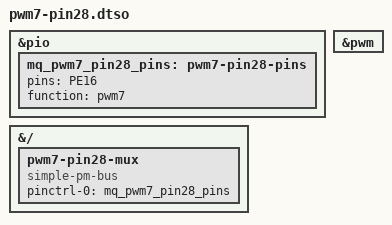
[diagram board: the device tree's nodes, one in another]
// SPDX-License-Identifier: (GPL-2.0+ OR MIT)
// Mangue OS header overlay pwm7-pin28 — GENERATED by tools/gen_overlays.py,
// edit overlays/header_table.py instead.
//
// pin port  role
//  28 PE16  pwm7
// device: /sys/class/pwm/pwmchip0 channel 7

/dts-v1/;
/plugin/;

#include <dt-bindings/gpio/gpio.h>
#include <dt-bindings/interrupt-controller/irq.h>
#include <dt-bindings/input/linux-event-codes.h>

&pio {
	mq_pwm7_pin28_pins: pwm7-pin28-pins {
		pins = "PE16";
		function = "pwm7";
	};
};

&pwm {
	status = "okay";
};

&{/} {
	pwm7-pin28-mux {
		compatible = "simple-pm-bus";
		pinctrl-names = "default";
		pinctrl-0 = <&mq_pwm7_pin28_pins>;
	};
};
